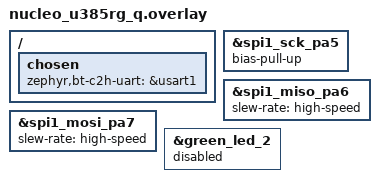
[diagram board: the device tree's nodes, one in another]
/*
 * Copyright (c) 2026 STMicroelectronics
 *
 * SPDX-License-Identifier: Apache-2.0
 */

&spi1_sck_pa5 {
	/delete-property/ bias-pull-down;
	bias-pull-up;
};

&spi1_miso_pa6 {
	slew-rate = "high-speed";
};

&spi1_mosi_pa7 {
	slew-rate = "high-speed";
};

/ {
	chosen {
		zephyr,bt-c2h-uart = &usart1;
	};
};

/* LD2 should be disabled while PA5 (Arduino D13) is configured as the SPI clock */
&green_led_2 {
	status = "disabled";
};
